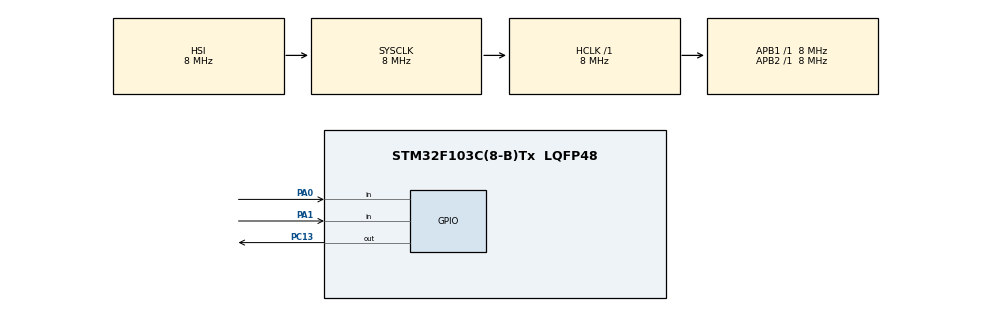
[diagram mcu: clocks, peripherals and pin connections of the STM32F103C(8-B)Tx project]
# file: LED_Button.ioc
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Mcu.Family=STM32F1
Mcu.Name=STM32F103C(8-B)Tx
Mcu.Package=LQFP48
NVIC.PriorityGroup=NVIC_PRIORITYGROUP_4
PA0-WKUP.GPIO_PuPd=GPIO_PULLUP
PA0-WKUP.Signal=GPIO_Input
PA1.GPIO_PuPd=GPIO_PULLUP
PA1.Signal=GPIO_Input
PA13.Mode=Serial_Wire
PA13.Signal=SYS_JTMS-SWDIO
PA14.Mode=Serial_Wire
PA14.Signal=SYS_JTCK-SWCLK
PC13-TAMPER-RTC.GPIO_PuPd=GPIO_NOPULL
PC13-TAMPER-RTC.PinState=GPIO_PIN_RESET
PC13-TAMPER-RTC.Signal=GPIO_Output
PD0-OSC_IN.Mode=HSE-External-Oscillator
PD0-OSC_IN.Signal=RCC_OSC_IN
PD1-OSC_OUT.Mode=HSE-External-Oscillator
PD1-OSC_OUT.Signal=RCC_OSC_OUT
ProjectManager.HeapSize=0x200
ProjectManager.StackSize=0x400
ProjectManager.TargetToolchain=MDK-ARM V5
RCC.AHBFreq_Value=8000000
RCC.APB1Freq_Value=8000000
RCC.APB1TimFreq_Value=8000000
RCC.APB2Freq_Value=8000000
RCC.APB2TimFreq_Value=8000000
RCC.HCLKFreq_Value=8000000
RCC.SYSCLKFreq_VALUE=8000000
RCC.USBFreq_Value=8000000
board=custom

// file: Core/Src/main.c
/* USER CODE BEGIN Header */
/**
  ******************************************************************************
  * @file           : main.c
  * @brief          : Main program body
  ******************************************************************************
  * @attention
  *
  * <h2><center>&copy; Copyright (c) 2023 STMicroelectronics.
  * All rights reserved.</center></h2>
  *
  * This software component is licensed by ST under BSD 3-Clause license,
  * the "License"; You may not use this file except in compliance with the
  * License. You may obtain a copy of the License at:
  *                        opensource.org/licenses/BSD-3-Clause
  *
  ******************************************************************************
  */
/* USER CODE END Header */
#include "main.h"

/* USER CODE BEGIN PV */
	uint8_t button_state;
/* USER CODE END PV */

void SystemClock_Config(void);
static void MX_GPIO_Init(void);

int main(void)
{

  /* MCU Configuration--------------------------------------------------------*/

  /* Reset of all peripherals, Initializes the Flash interface and the Systick. */
  HAL_Init();

  /* Configure the system clock */
  SystemClock_Config();

  /* Initialize all configured peripherals */
  MX_GPIO_Init();

  /* Infinite loop */
  while (1)
  {

    /* USER CODE BEGIN 3 */
		button_state = HAL_GPIO_ReadPin(GPIOA, GPIO_PIN_0);
		if (button_state == RESET)
		{
			HAL_GPIO_TogglePin(GPIOC, GPIO_PIN_13);
			HAL_Delay(500);
		}
  }
  /* USER CODE END 3 */
}

void SystemClock_Config(void)
{
  RCC_OscInitTypeDef RCC_OscInitStruct = {0};
  RCC_ClkInitTypeDef RCC_ClkInitStruct = {0};

  /** Initializes the RCC Oscillators according to the specified parameters
  * in the RCC_OscInitTypeDef structure.
  */
  RCC_OscInitStruct.OscillatorType = RCC_OSCILLATORTYPE_HSI;
  RCC_OscInitStruct.HSIState = RCC_HSI_ON;
  RCC_OscInitStruct.HSICalibrationValue = RCC_HSICALIBRATION_DEFAULT;
  RCC_OscInitStruct.PLL.PLLState = RCC_PLL_NONE;
  if (HAL_RCC_OscConfig(&RCC_OscInitStruct) != HAL_OK)
  {
    Error_Handler();
  }
  /** Initializes the CPU, AHB and APB buses clocks
  */
  RCC_ClkInitStruct.ClockType = RCC_CLOCKTYPE_HCLK|RCC_CLOCKTYPE_SYSCLK
                              |RCC_CLOCKTYPE_PCLK1|RCC_CLOCKTYPE_PCLK2;
  RCC_ClkInitStruct.SYSCLKSource = RCC_SYSCLKSOURCE_HSI;
  RCC_ClkInitStruct.AHBCLKDivider = RCC_SYSCLK_DIV1;
  RCC_ClkInitStruct.APB1CLKDivider = RCC_HCLK_DIV1;
  RCC_ClkInitStruct.APB2CLKDivider = RCC_HCLK_DIV1;

  if (HAL_RCC_ClockConfig(&RCC_ClkInitStruct, FLASH_LATENCY_0) != HAL_OK)
  {
    Error_Handler();
  }
}

static void MX_GPIO_Init(void)
{
  GPIO_InitTypeDef GPIO_InitStruct = {0};

  /* GPIO Ports Clock Enable */
  __HAL_RCC_GPIOC_CLK_ENABLE();
  __HAL_RCC_GPIOD_CLK_ENABLE();
  __HAL_RCC_GPIOA_CLK_ENABLE();

  /*Configure GPIO pin Output Level */
  HAL_GPIO_WritePin(GPIOC, GPIO_PIN_13, GPIO_PIN_RESET);

  /*Configure GPIO pin : PC13 */
  GPIO_InitStruct.Pin = GPIO_PIN_13;
  GPIO_InitStruct.Mode = GPIO_MODE_OUTPUT_PP;
  GPIO_InitStruct.Pull = GPIO_NOPULL;
  GPIO_InitStruct.Speed = GPIO_SPEED_FREQ_LOW;
  HAL_GPIO_Init(GPIOC, &GPIO_InitStruct);

  /*Configure GPIO pins : PA0 PA1 */
  GPIO_InitStruct.Pin = GPIO_PIN_0|GPIO_PIN_1;
  GPIO_InitStruct.Mode = GPIO_MODE_INPUT;
  GPIO_InitStruct.Pull = GPIO_PULLUP;
  HAL_GPIO_Init(GPIOA, &GPIO_InitStruct);

}

void Error_Handler(void)
{
}

/************************ (C) COPYRIGHT STMicroelectronics *****END OF FILE****/
